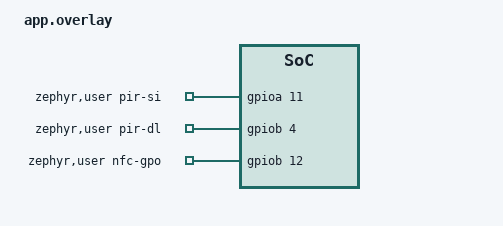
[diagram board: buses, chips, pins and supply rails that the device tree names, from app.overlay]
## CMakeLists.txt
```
#
# Copyright (c) 2025 HARDWARIO a.s.
#
# SPDX-License-Identifier: Apache-2.0
#

cmake_minimum_required(VERSION 3.20.0)

# Debug build (debug.conf in EXTRA_CONF_FILE): also apply debug.overlay, which
# locks the MSI to the LSE (msi-pll-mode). debug.conf sets CONFIG_PM=n, so the
# kernel tick is SysTick on the free-running MSI (~1.2 % off) instead of LPTIM
# on the LSE. Kconfig cannot add a devicetree overlay, and Kconfig is not
# parsed yet here, so key on the fragment name before find_package(Zephyr).
if(EXTRA_CONF_FILE MATCHES "(^|;|/)debug\\.conf(;|$)")
  list(APPEND EXTRA_DTC_OVERLAY_FILE ${CMAKE_CURRENT_SOURCE_DIR}/debug.overlay)
endif()

find_package(Zephyr REQUIRED HINTS $ENV{ZEPHYR_BASE})
project(sticker)

# Module patches (zephyr/patches.yml, applied by `west patch apply`). A LoRaWAN
# image built without them silently misses the fix, so refuse to build instead.
# Each patch leaves a "STICKER-<issue>" marker in the patched source. Checked at
# configure time and again on every build: `west update` resets the module and
# an incremental build (incl. the one `west flash` runs) does not reconfigure.
if(CONFIG_LORAWAN AND DEFINED ZEPHYR_LORAMAC_NODE_MODULE_DIR AND NOT STICKER_ALLOW_UNPATCHED_MODULES)
  set(FILE ${ZEPHYR_LORAMAC_NODE_MODULE_DIR}/src/mac/LoRaMac.c)
  set(MARKER STICKER-419)
  include(${CMAKE_CURRENT_SOURCE_DIR}/cmake/check_module_patch.cmake)
  add_custom_target(sticker_module_patch_check ALL
    COMMAND ${CMAKE_COMMAND} -DFILE=${FILE} -DMARKER=${MARKER}
            -P ${CMAKE_CURRENT_SOURCE_DIR}/cmake/check_module_patch.cmake
    COMMENT "Checking STICKER module patches")
  add_dependencies(app sticker_module_patch_check)
endif()

# Firmware version + source baked into the image (logged at boot, reported by
# the GetInfo command). CI passes the numeric version components and build type
# via -DAPP_VERSION_* / -DAPP_BUILD_TYPE (see .github/workflows/build.yml):
#   tag v1.3.4 -> 1/3/4, type 0 (MAIN)
#   branch/PR  -> the version below, type 1 (DEV)
# Local builds (no override) use the version below and are type 2 (CUSTOM).
# Keep it at the release this branch builds towards. The debug/release config
# is a separate axis (CONFIG_FW_DEBUG), not set here.
if(NOT DEFINED APP_VERSION_MAJOR)
  set(APP_VERSION_MAJOR 2)
  set(APP_VERSION_MINOR 0)
  set(APP_VERSION_PATCH 0)
endif()
if(NOT DEFINED APP_BUILD_TYPE)
  set(APP_BUILD_TYPE 2) # CUSTOM
endif()
add_compile_definitions(
  APP_VERSION_MAJOR=${APP_VERSION_MAJOR}
  APP_VERSION_MINOR=${APP_VERSION_MINOR}
  APP_VERSION_PATCH=${APP_VERSION_PATCH}
  APP_BUILD_TYPE=${APP_BUILD_TYPE})
message(STATUS "Firmware version: ${APP_VERSION_MAJOR}.${APP_VERSION_MINOR}.${APP_VERSION_PATCH} (build type ${APP_BUILD_TYPE})")

# Shared headers (sticker/drivers/...) live in the repo's top-level include/.
target_include_directories(app PRIVATE ${CMAKE_CURRENT_SOURCE_DIR}/../include)

list(APPEND CMAKE_MODULE_PATH ${ZEPHYR_BASE}/modules/nanopb)
include(nanopb)

# Note: nanopb generates src/app_config.pb.{c,h} here; west configen generates
# src/app_config.{c,h} (struct/Settings/shell) from app_config.yml. Different
# extensions, same stem — no clash.
zephyr_nanopb_sources(app src/app_config.proto)

target_sources_ifdef(CONFIG_ADC app PRIVATE src/app_analog.c)
target_sources_ifdef(CONFIG_ADC app PRIVATE src/app_battery.c)
target_sources_ifdef(CONFIG_RADIO_P2P app PRIVATE src/app_radio_p2p.c)
target_sources_ifdef(CONFIG_DS28E17 app PRIVATE src/app_machine_probe.c)
target_sources_ifdef(CONFIG_LIS2DH app PRIVATE src/app_accel.c)
target_sources_ifdef(CONFIG_LORAWAN app PRIVATE src/app_radio_lrw.c)
# app_report.c owns the periodic sample/history cadence via app_radio, not
# just the LoRaWAN uplink -- compiled unconditionally so sampling,
# history capture and store-and-forward keep working with no radio linked in
# at all. Two independent reasons converge here: #395's CONFIG_RADIO_LORAWAN=n
# debug variant, and #118's P2P bench overlay (CONFIG_RADIO_LORAWAN=n +
# CONFIG_RADIO_P2P=y). Its own app_radio_* calls route to whichever transport
# is compiled in, and app_radio.c handles "neither" itself.
target_sources(app PRIVATE src/app_report.c)
target_include_directories_ifdef(CONFIG_LORAWAN app PRIVATE
  ${ZEPHYR_LORAMAC_NODE_MODULE_DIR}/src/mac
  ${ZEPHYR_LORAMAC_NODE_MODULE_DIR}/src/mac/region
  ${ZEPHYR_LORAMAC_NODE_MODULE_DIR}/src/system
  ${ZEPHYR_LORAMAC_NODE_MODULE_DIR}/src/boards
)
target_sources_ifdef(CONFIG_OPT3001 app PRIVATE src/app_opt3001.c)
target_sources_ifdef(CONFIG_MPL3115A2 app PRIVATE src/app_mpl3115a2.c)
target_sources_ifdef(CONFIG_POWEROFF app PRIVATE src/app_power.c)
target_sources_ifdef(CONFIG_SHELL app PRIVATE src/app_ats.c)
target_sources_ifdef(CONFIG_SHT4X app PRIVATE src/app_sht4x.c)
target_sources_ifdef(CONFIG_W1 app PRIVATE src/app_ds18b20.c)
target_sources_ifdef(CONFIG_W1 app PRIVATE src/app_w1.c)
target_sources_ifdef(CONFIG_W1 app PRIVATE src/app_w1_slots.c)
target_sources_ifdef(CONFIG_WATCHDOG app PRIVATE src/app_wdog.c)
target_sources_ifdef(CONFIG_APP_BUZZER app PRIVATE src/app_buzzer.c)
target_sources_ifdef(CONFIG_APP_CALIBRATION app PRIVATE src/app_calibration.c)
target_sources(app PRIVATE src/app_alarm.c)
target_sources(app PRIVATE src/app_alarm_rules.c)
target_sources(app PRIVATE src/app_clock.c)
target_sources(app PRIVATE src/app_cmd.c)
target_sources(app PRIVATE src/app_compose.c)
target_sources(app PRIVATE src/app_config.c)
target_sources(app PRIVATE src/app_counters.c)
target_sources(app PRIVATE src/app_eventlog.c)
target_sources(app PRIVATE src/app_hall.c)
target_sources(app PRIVATE src/app_history.c)
target_sources(app PRIVATE src/app_input.c)
target_sources(app PRIVATE src/app_led.c)
target_sources(app PRIVATE src/app_config_ingest.c)
target_sources(app PRIVATE src/app_nfc.c)
target_sources(app PRIVATE src/app_ccm.c)

# app_ccm's block cipher: the STM32WL HW AES peripheral by default. When it is
# disabled (CONFIG_APP_CCM_HW_AES=n, e.g. the variant-A soft fallback) the CCM
# layer uses the LoRaMac soft-SE AES instead — pull that source + its prekeyed
# API in (the HW build needs neither).
# With LoRaWAN on, the loramac-node library already links that aes.c.
if(NOT CONFIG_APP_CCM_HW_AES)
  set(SOFT_SE_DIR ${ZEPHYR_LORAMAC_NODE_MODULE_DIR}/src/peripherals/soft-se)
  if(NOT CONFIG_HAS_SEMTECH_SOFT_SE)
    target_sources(app PRIVATE ${SOFT_SE_DIR}/aes.c)
  endif()
  target_include_directories(app PRIVATE ${SOFT_SE_DIR})
  set_source_files_properties(src/app_ccm.c ${SOFT_SE_DIR}/aes.c
    PROPERTIES COMPILE_DEFINITIONS "AES_ENC_PREKEYED")
endif()
target_sources_ifdef(CONFIG_APP_PYQ1648 app PRIVATE src/app_pyq1648.c)
target_sources(app PRIVATE src/app_sensor.c)
# Generated by `west sensorgen` from src/app_sensor_types.yaml (#430).
target_sources(app PRIVATE src/app_sensor_types.c)
target_sources(app PRIVATE src/app_settings.c)
target_sources(app PRIVATE src/app_radio.c)
target_sources(app PRIVATE src/app_slot.c)
target_sources(app PRIVATE src/main.c)
```

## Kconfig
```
#
# Copyright (c) 2025 HARDWARIO a.s.
#
# SPDX-License-Identifier: Apache-2.0
#

menu "Application"

config RADIO_LORAWAN
	bool "LoRaWAN radio transport"
	default y
	select LORAWAN if LORA
	help
	  App-level name for the LoRaWAN transport (issue #395) — pairs with
	  RADIO_P2P below as the two selectable radio transports. `select
	  LORAWAN if LORA` only forces the underlying Zephyr subsystem ON
	  when this is y AND the LORA radio driver is present (native_sim
	  test builds have neither — `select` on a symbol whose own
	  dependencies aren't met is a hard Kconfig error, not a silent
	  no-op, hence the `if LORA` guard); turning this off on real HW
	  (nothing else in this tree selects LORAWAN) leaves it at its own
	  default (off), disabling all radio transmission. Telemetry/alarm
	  sampling and history capture keep working with no radio
	  (app_report.c owns that cadence, not the uplink) — only the actual
	  send is skipped.

	  ~41 KB flash / ~15 KB RAM when off (issue #395) — the single
	  biggest lever of any toggle in this tree, but also the biggest
	  behavioral change (no radio at all), which is why it stays on by
	  default rather than joining debug.conf's OFF-by-default set.

config RADIO_P2P
	bool "Raw-LoRa P2P radio transport (#118)"
	depends on LORA
	default y
	# TOWER's ACK window: TX-done straight into RX (doc/plan/470 §13.1).
	# Without it (native_sim, a driver lacking it) app_radio_p2p.c falls
	# back to lora_send() + lora_recv_async().
	imply LORA_SEND_RECV_ASYNC
	# Boosted LNA gain on every lora_* reception, ~+2 dB for ~+0.1 uA at a
	# 900 s report (doc/plan/470 §3.3, Hynek 2026-10-08).
	imply LORA_RX_BOOSTED_GAIN
	# The fsk PHY profile, TOWER-native GFSK (#490); without it
	# p2p-modulation fsk refuses to start.
	imply LORA_FSK
	# The fsk packet's CRC16 is computed in software (p2p_fsk_wrap()).
	select CRC
	help
	  App-level name for the raw-LoRa point-to-point transport
	  (app_radio_p2p.c, issue #118) — pairs with RADIO_LORAWAN above as the two
	  selectable radio transports. Reserved as an inert placeholder by
	  #395 and wired up here when the P2P work merged; it was briefly
	  named APP_LORA_P2P on the feat-p2p branch, so out-of-tree overlays
	  carrying that name need updating.

	  Unlike RADIO_LORAWAN, which `select`s an underlying Zephyr
	  subsystem, this compiles app-owned code that talks to drivers/lora
	  directly — hence `depends on LORA` rather than a `select` (and it
	  therefore drops out on native_sim test builds, which have no radio,
	  without needing RADIO_LORAWAN's `if LORA` guard).

	  Which transport actually brings up the shared SX126x radio is a
	  runtime choice (`radio-mode`, #271), not a build-time one: both
	  stacks link into the same image when both are y. Turning this off
	  reclaims flash on builds that never need P2P — the flash-tight
	  debug overlay does exactly that (doc/p2p.md §11).

config APP_VERBOSE_LOGGING
	bool "Enable verbose parameter logging"
	default y
	help
	  Enable verbose logging of all configuration parameters.
	  This adds detailed logging for NFC parameters and other
	  configuration changes. Disable to save flash space.

config FW_DEBUG
	bool "Debug firmware indication"
	default n
	help
	  Enable debug firmware LED indication.
	  When enabled, the periodic LED blink shows green + yellow
	  instead of just green to indicate debug build.

config APP_DEBUG_AUTOSUSPEND_S
	int "Debug auto-suspend idle timeout (seconds, 0 = disabled)"
	depends on FW_DEBUG && POWEROFF && SHELL_BACKEND_RTT
	default 7200
	help
	  On the Debug build, after this many seconds with no RTT/shell
	  activity the device enters deep-sleep (STM32 Shutdown via
	  sys_poweroff) so a forgotten bench unit stops draining its
	  battery — Debug FW runs with CONFIG_PM=n, so the CPU never sleeps
	  and the quiescent draw is high. Default 7200 s (2 h). 0 disables
	  the auto-suspend.
	  Wake is by NRST / power-cycle (clean boot; NVS identity and
	  LoRaWAN keys survive in flash).

config APP_BATTERY_BOOT_GATE
	bool "Stay off when the battery is too low at boot"
	default y
	depends on HAS_POWEROFF && ADC
	select POWEROFF
	help
	  #496: measure the battery first thing at boot, before the IWDG,
	  the radio, NVS writes and the sensors. Below
	  APP_BATTERY_BOOT_MIN_MV the STICKER does not start: it powers
	  down to STM32WL Shutdown and stays off until NRST / a
	  power-cycle (battery replacement) runs the check again. A
	  depleted cell otherwise boot-loops on brownout, writing the P2P
	  FCnt base to flash and sending a Hello on every boot. A failed
	  ADC read boots normally.

config APP_BATTERY_BOOT_MIN_MV
	int "Minimum battery voltage to start (mV)"
	depends on APP_BATTERY_BOOT_GATE
	default 1800
	range 1000 3600
	help
	  Battery voltage below which the STICKER stays off at boot
	  (APP_BATTERY_BOOT_GATE). 1.8 V is the STM32WLE5 / flash minimum
	  (1.71 V) plus margin. Independent of the low-battery alarm
	  threshold (`battery_level`).

config APP_LORAWAN_1_1
	bool "Use LoRaWAN 1.1.x crypto for OTAA"
	default n
	help
	  Enable LoRaWAN 1.1.x crypto for OTAA join: feed `lrw_nwkkey` into
	  the NwkKey slot (distinct from AppKey). When disabled (default,
	  LoRaWAN 1.0.x), the firmware copies `radio_appkey` into both the
	  NwkKey and AppKey slots so the JoinRequest MIC is computed from
	  AppKey — required for 1.0.x network servers (TTN, ChirpStack,
	  Helium).

	  Enabling this also requires the LoRaMac library to be built with
	  USE_LRWAN_1_1_X_CRYPTO=1; the Kconfig only flips the app-level
	  key wiring.

config APP_NFC_ENCRYPTION
	bool "Encrypt the NFC command/config channel (AES-CCM)"
	default y
	help
	  Production default (y): NFC command records (hio.stck:cmd) and config
	  records (hio.stck:cfg) must be AES-CCM encrypted with the device
	  secret_key and a strictly increasing nonce, and the response written
	  back (hio.stck:rsp) is encrypted the same way. Without the key, the
	  only thing a phone can read is the plaintext info record (hio.stck:inf).

	  Disable (n) ONLY for a bench validation build, to drive the NFC command
	  and config channel in plaintext without provisioning a secret key or
	  managing nonces. Such a build logs a loud boot warning. NEVER ship a
	  build with this turned off.

config APP_CCM_HW_AES
	bool "Use the STM32WL hardware AES peripheral for NFC AES-CCM"
	depends on APP_NFC_ENCRYPTION && SOC_SERIES_STM32WLX
	default y
	help
	  Back the app_ccm (RFC 3610 AES-CCM) block cipher with the STM32WL on-die
	  AES peripheral (register-level, no HAL/Zephyr-crypto dependency). This is
	  what lets the build drop mbedTLS entirely (~6.5 KB flash, #261).

	  Disable (n) to fall back to the LoRaMac soft-SE AES (peripherals/soft-se,
	  already in flash) as the block cipher instead — the CCM layer is identical,
	  only the primitive differs. The host unit tests use this software path.

config APP_CMD_DEBUG_SHELL
	bool "Shell injector for downlink command dispatcher"
	depends on SHELL
	default n
	help
	  Enable `tester cmd <transport> <hex>` for end-to-end testing
	  of the downlink command dispatcher without a LoRaWAN gateway.
	  The hex payload is fed to app_cmd_handle as if it had arrived
	  from the given transport (lrw or nfc) and the encoded response
	  is logged and (for lrw) queued on port 85.

config APP_HISTORY
	bool "Sensor history store-and-forward"
	default y
	help
	  Disable to drop the history (and the event log) entirely, e.g. in the
	  provisioning image. History commands then report no data.

config APP_HISTORY_FLASH
	bool "Persist sensor history in the history_partition flash"
	depends on APP_HISTORY
	default y
	help
	  Store the sensor history store-and-forward buffer in the dedicated
	  history_partition flash (NVS), surviving reboot and power loss.
	  Disable to use a __noinit RAM ring of CONFIG_APP_HISTORY_BYTES
	  instead; data is then lost on power loss.

	  Builds with this enabled must keep CONFIG_FLASH_LOAD_SIZE at the
	  history_partition offset so the linker stops the image from growing
	  into the runtime-written flash (see prj.conf); builds with it
	  disabled (debug.conf) may relax the budget up to the
	  storage_partition offset.

config APP_HISTORY_BYTES
	int "History RAM fallback ring size (bytes)"
	default 1024
	help
	  Size of the in-RAM history ring used when CONFIG_APP_HISTORY_FLASH=n.
	  Record size is variable (5-33 B) depending on the enabled sensor set.

config APP_CALIBRATION
	bool "Factory calibration mode (magnet-triggered)"
	default y
	help
	  Compile in the magnet-triggered factory calibration mode
	  (app_calibration.c): boots into a dedicated LED/LoRaWAN test loop
	  that reads every enabled sensor and reports over a fixed uplink,
	  instead of normal application behavior.

	  Disable for bench sessions that don't need to calibrate hardware
	  (e.g. a pure radio/transport test) to free flash/RAM for what IS
	  under test — see app/debug.conf's variant table.

config APP_PYQ1648
	bool "PIR motion sensor (PYQ1648)"
	default y
	help
	  Compile in the PIR motion-detector driver wrapper (app_pyq1648.c).
	  Default y to match shipped behavior — both this and
	  CONFIG_APP_BUZZER stay compiled in on a normal build, since which
	  one is actually active is a runtime, per-unit choice
	  (cap-gpio-mode pir / buzzer, they share pins, #90/#338/#498).
	  Disable only for a bench session that knows it needs neither.

config APP_BUZZER
	bool "Buzzer / melody output (#338)"
	default y
	help
	  Compile in the buzzer/melody driver wrapper (app_buzzer.c) and its
	  shell (`ats buzz ...`) and remote-command (NFC/LoRaWAN play-melody)
	  surfaces. Default y to match shipped behavior (see
	  CONFIG_APP_PYQ1648 above) — disable only for a bench session that
	  knows it needs neither PIR nor buzzer.

endmenu

menu "Zephyr Kernel"
source "Kconfig.zephyr"
endmenu
```

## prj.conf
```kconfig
# System heap backs only the 1-Wire bus scan (app_w1.c), which k_mallocs one
# ~16 B scan_item per ROM up to APP_W1_SCAN_MAX=32 (≈768 B incl. sys_heap block
# overhead). 1024 B holds the full 32-device cap with margin; the old 2048 was
# ~2x oversized (#221.2).
CONFIG_HEAP_MEM_POOL_SIZE=1024
CONFIG_IDLE_STACK_SIZE=512
# ISR/main sized from HW high-water marks (CONFIG_INIT_STACKS, 2026-10-09,
# release + debug, join/report/downlink/SetParam/GetConfig): ISR 192 B, main
# 992 B (boot incl. settings load and the boot ConfigDump). >= 2x margin.
CONFIG_ISR_STACK_SIZE=1024
CONFIG_MAIN_STACK_SIZE=2048
CONFIG_SYSTEM_WORKQUEUE_STACK_SIZE=2048

CONFIG_REBOOT=y
# Drop the "*** Booting Zephyr ***" banner (~0.3 KB flash, #220); the boot log
# line "Firmware version: ..." is our own LOG_INF and is unaffected.
CONFIG_BOOT_BANNER=n
# Release has no console backend, so printk() output and the fault-dump text go
# nowhere — yet printk, the libc vfprintf behind it and the fault-dump strings
# cost ~3 KB flash. Faults still reset the device and the reset cause stays
# visible in GetInfo (HWINFO, #88). debug.conf turns both back on.
CONFIG_PRINTK=n
CONFIG_FAULT_DUMP=0
CONFIG_I2C=y
# Bus recovery (H-6): app_sensor calls i2c_recover_bus() after a run of failed
# reads to bit-bang 9 clocks and free a wedged bus; without this it returns
# -ENOSYS and a stuck bus leaves every onboard sensor permanently dead. Needs
# scl-gpios/sda-gpios on the &i2c1 node (board DTS).
CONFIG_I2C_STM32_BUS_RECOVERY=y
CONFIG_SENSOR=y
CONFIG_PM=y
CONFIG_PM_DEVICE=y
# Device runtime PM stays ON (low idle current: it on-demand-suspends idle
# peripherals — worth ~200 µA vs disabling it globally, measured on HW). The
# NFC-on-release failure it caused is handled in the NFC layer, not by turning PM
# off: servicing one encrypted tag command is many back-to-back i2c1 transfers
# and, on release, the CPU dropped into Stop2 in the field-off gaps between them,
# which corrupts the i2c1 (ST25DV) tag I/O (release-only; debug runs PM=n and
# never sleeps). app_nfc.c now holds a SUSPEND_TO_IDLE policy lock for the whole
# RF session (nfc_keep_awake, armed from the GPO ISR on RF field-on/write), so no
# Stop2 lands mid-operation; the lock is released after a short RF-quiet window so
# deep sleep resumes. The NFC poll is also event-driven (waits forever on the GPO
# when idle, no periodic Stop2 wake). Validated on hardware.
CONFIG_PM_DEVICE_RUNTIME=y

CONFIG_SPI=y

CONFIG_NVS=y
CONFIG_FLASH=y
CONFIG_FLASH_MAP=y
CONFIG_SETTINGS=y
# Without these a full settings_save() walks every NVS name record for every
# key: 3-4 s of CPU, longer than a radio exchange may wait for it (app_radio.c).
CONFIG_NVS_LOOKUP_CACHE=y
CONFIG_SETTINGS_NVS_NAME_CACHE=y
CONFIG_CRC=y # history ring page-header integrity (app_history.c, #265)

# Link-Time Optimization: defer final codegen to link time so the compiler sees
# the whole program and eliminates dead code across translation-unit boundaries
# (LoRaMac Class B/C + FUOTA variants STICKER never calls).
# Reclaims ~19 KB flash (release ~99.9% → ~88.5%), restoring headroom for bug
# fixes that otherwise fail to link (#263). ISR_TABLES_LOCAL_DECLARATION is
# required for the vector table to build correctly under LTO. Note: setting
# CONFIG_LTO=y on the west command line silently does not apply — keep it here.
CONFIG_LTO=y
CONFIG_ISR_TABLES_LOCAL_DECLARATION=y

# Image size budget — must equal the history_partition offset (sticker.dts):
# with CONFIG_APP_HISTORY_FLASH=y (release default) the history ring rewrites
# that area at runtime, and NVS settings + LoRaWAN NVM always rewrite the
# storage_partition. An image leaking into either region gets corrupted in
# flash → hard fault on next boot, recoverable only by mass erase. With this
# set, the linker fails the build instead ("region ROM overflowed").
# #265 grew this 0x28000 → 0x2C000 (code 160 KB → 176 KB) after the history
# partition shrank to 64 KB @ 0x2C000; #302 grew it again 0x2C000 → 0x34000
# (code 176 KB → 208 KB) after history shrank further to 32 KB @ 0x34000.
# debug.conf (history in RAM) relaxes this to the storage offset 0x3C000.
CONFIG_FLASH_LOAD_SIZE=0x34000

CONFIG_LORA=y
CONFIG_LORAMAC_REGION_AS923=y
CONFIG_LORAMAC_REGION_AU915=y
CONFIG_LORAMAC_REGION_EU868=y
CONFIG_LORAMAC_REGION_US915=y
CONFIG_LORAWAN_NVM_SETTINGS=y
# CONFIG_LORAWAN itself now comes from CONFIG_RADIO_LORAWAN's `select`
# (app/Kconfig, default y, issue #395) instead of a flat assignment here —
# turning CONFIG_RADIO_LORAWAN off (e.g. debug.conf's radio-free bench
# profile) is the one place that needs to change.
# CONFIG_LORAWAN_SYSTEM_MAX_RX_ERROR stays at the Zephyr default (20). Larger
# values overflow the uint8 RX symbol timeout in the SX126x driver on fast RX1
# data rates (US915 DR>=2, EU868 DR6) and every downlink is lost.
# Bounded MAC-confirm wait in lorawan_join()/lorawan_send() (sticker-zephyr,
# #181): a lost confirm returns -ETIMEDOUT instead of wedging m_work_q. Must stay
# below LRW_HEARTBEAT_TIMEOUT_MS (30 s, app_radio_lrw.c, BUILD_ASSERT) so the graceful
# path wins over the #182 watchdog-liveness reset; legitimate waits are ~7-10 s.
CONFIG_LORAWAN_CONFIRM_TIMEOUT_MS=20000

# Wall-clock: STM32 RTC (LSE-backed) set from LoRaWAN DeviceTimeReq. See app_clock.c.
CONFIG_RTC=y
CONFIG_RTC_STM32=y

CONFIG_LIS2DH_ACCEL_RANGE_4G=y
CONFIG_LIS2DH_BLOCK_DATA_UPDATE=y
CONFIG_LIS2DH_ODR_5=y
CONFIG_LIS2DH_OPER_MODE_LOW_POWER=y
CONFIG_LIS2DH_TRIGGER_GLOBAL_THREAD=y

CONFIG_ENTROPY_GENERATOR=y

CONFIG_WATCHDOG=y
CONFIG_WDT_DISABLE_AT_BOOT=y

# Reset-cause readback reported in GetInfo so watchdog/brownout resets are
# visible in the field (#88).
CONFIG_HWINFO=y

CONFIG_ADC=y

CONFIG_LIS2DH=y
CONFIG_MPL3115A2=y
CONFIG_OPT3001=y
CONFIG_SHT4X=y
CONFIG_W1=y

CONFIG_NET_BUF=y
CONFIG_NANOPB=y

# mbedTLS is gone (#261): the NFC AES-CCM channel is now served by app_ccm (RFC
# 3610) over the STM32WL on-die AES peripheral, saving ~6.5 KB flash. LoRaMac uses
# its own soft-SE AES, independent of this.
```

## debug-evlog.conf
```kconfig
# Event log bench image: layer on debug.conf + debug-history-flash.conf
# (with debug-history-flash.overlay). Real flash ring for history + event log,
# RTT shell + logs, accelerometer on; drops what the motion test does not need
# to fit the 224 KB code partition. EU868 only (debug.conf), no 1-Wire.
CONFIG_LIS2DH=y
CONFIG_SHT4X=n
CONFIG_OPT3001=n
CONFIG_APP_CALIBRATION=n
CONFIG_APP_BUZZER=n
CONFIG_APP_PYQ1648=n
CONFIG_W1=n
CONFIG_LOG=n
CONFIG_SHELL_HELP=n
CONFIG_SHELL_HELP_ON_WRONG_ARGUMENT_COUNT=n
```

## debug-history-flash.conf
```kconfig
# Copyright (c) 2026 HARDWARIO a.s.
# SPDX-License-Identifier: Apache-2.0
#
# Pair with debug-history-flash.overlay (16 KB history_partition @ 0x38000,
# code_partition grown to 224 KB). Overrides debug.conf's history-in-RAM
# fallback so a debug build (full RTT shell) can exercise the real flash-ring
# backend: persistence across reboot, page wrap/eviction (8 x 2 KB pages wrap
# in minutes, not hours), torn-tail recovery, and the clock-sync base-time
# backfill (app_history_on_clock_sync) — none of which are testable on a
# stock debug build (CONFIG_APP_HISTORY_FLASH=n) or a stock release build (no
# shell to drive `history *` / `w1` / `alarm` interactively).
#
# Usage: west build -b sticker . -p always -- \
#   -DEXTRA_CONF_FILE="debug.conf;debug-history-flash.conf" \
#   -DEXTRA_DTC_OVERLAY_FILE=debug-history-flash.overlay

CONFIG_APP_HISTORY_FLASH=y

# Must match debug-history-flash.overlay's code_partition size (224 KB) — the
# linker fails the build ("region ROM overflowed") instead of letting the
# image grow into the runtime-written history_partition (see prj.conf).
CONFIG_FLASH_LOAD_SIZE=0x38000
```

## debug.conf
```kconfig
# Float printf support is not needed: all %f log/shell output was converted to
# integer formatting (APP_FP* in app_log.h), freeing debug flash.
CONFIG_CBPRINTF_FP_SUPPORT=n
# prj.conf turns printk and the fault dump off for release (no console there);
# debug keeps both — RTT console output and readable fault reports.
CONFIG_PRINTK=y
CONFIG_FAULT_DUMP=2

CONFIG_FW_DEBUG=y

CONFIG_CONSOLE=y
CONFIG_RTT_CONSOLE=y

CONFIG_THREAD_NAME=y

CONFIG_USE_SEGGER_RTT=y

CONFIG_LOG=n

# Logging mode: MINIMAL routes LOG_* straight to printk (-> RTT console via
# CONFIG_RTT_CONSOLE), with no deferred log thread, no internal buffer and no
# backend layer. Saves ~14 KB flash + ~11 KB RAM vs deferred mode. Trade-off:
# no timestamps/prefixes in the log line, and build-time level filtering only
# (CONFIG_LOG_MAX_LEVEL still applies, but the `log` shell cmd can't change
# levels at runtime).
# CONFIG_LOG_MODE_MINIMAL=y

# --- Deferred-logging config (full RTT backend, timestamps, runtime levels) ---
# ENABLED (was MINIMAL): MINIMAL routes LOG_* synchronously via printk, which
# blocks the calling context long enough to make the STICKER miss the tight
# high-DR (SF7) Class-A RX1 window -> downlinks (e.g. fPort 85 req_history) are
# not received. Deferred mode drains logs on a separate thread with a DROP-mode
# backend, so logging never stalls the RX timing. (~14 KB flash / ~11 KB RAM.)
# Buffers trimmed vs the reference block to fit the near-full debug RAM budget
# (deferred adds ~11 KB; default 2048 sizes overflowed RAM by ~1.7 KB).

CONFIG_SHELL=y
CONFIG_SHELL_BACKEND_RTT_BUFFER=0
CONFIG_SHELL_BACKEND_RTT=y
CONFIG_SHELL_ECHO_STATUS=n
CONFIG_SHELL_HELP_ON_WRONG_ARGUMENT_COUNT=y
CONFIG_SHELL_HELP=y
CONFIG_SHELL_LOG_BACKEND=n
CONFIG_SHELL_MINIMAL=y
CONFIG_SHELL_PROMPT_RTT=""
CONFIG_SHELL_RTT_RX_POLL_PERIOD=200
CONFIG_SHELL_STACK_SIZE=4096
CONFIG_SHELL_VT100_COMMANDS=n

# I2C/LoRa-PHY shells dropped to keep the debug image inside the
# CONFIG_FLASH_LOAD_SIZE budget (see prj.conf); re-enable locally if needed.
CONFIG_I2C_SHELL=n

# Down (host->target, shell RX) doesn't need to match the up/log buffer: the
# Zephyr default is 16 B, but the shell needs enough for a full command line
# (e.g. `ats cmd <hex>` payloads) — 256 B is a comfortable compromise, freeing
# ~768 B of RAM that was otherwise just mirroring the up-buffer size for no
# documented reason.
CONFIG_SEGGER_RTT_BUFFER_SIZE_DOWN=256
CONFIG_SEGGER_RTT_BUFFER_SIZE_UP=1024

CONFIG_SEGGER_RTT_SECTION_CUSTOM=y

CONFIG_PM=n

# Deep-sleep / auto-suspend (#113): sys_poweroff() puts the STM32WL into Shutdown
# after CONFIG_APP_DEBUG_AUTOSUSPEND_S of RTT/shell inactivity, so a forgotten
# debug unit (PM=n, CPU never sleeps) stops draining its battery. Wake = NRST.
CONFIG_POWEROFF=y

CONFIG_LORA_LOG_LEVEL_DBG=n
CONFIG_SENSOR_LOG_LEVEL_DBG=n
CONFIG_W1_LOG_LEVEL_DBG=n

# Debug-only region trim (release keeps AS923/AU915/US915): the bench only ever
# exercises EU868 (TTN + ChirpStack), and the near-full debug image needs the
# flash/RAM headroom. Measured ~5.9 KB flash / ~0.7 KB RAM for AU915+US915
# (2026-06-17 analysis); AS923 adds ~2.6 KB flash (#409 A6). A trimmed region
# stored in NVM leaves the radio silent (#409 A1), never on the wrong band.
CONFIG_LORAMAC_REGION_AS923=n
CONFIG_LORAMAC_REGION_AU915=n
CONFIG_LORAMAC_REGION_US915=n

CONFIG_LORA_SHELL=n

# Debug drops the P2P transport (release keeps it, default y): the near-full
# debug image only has ~4.75 KB headroom vs release's ~58.5 KB (doc/p2p.md
# §11, measured 2026-08-17) — not enough for the dual-stack addition.
CONFIG_RADIO_P2P=n

# The 3 new p2p_* config fields (#118) grow g_app_config (BSS) by 12 B even
# with CONFIG_RADIO_P2P=n above -- config schema size is independent of
# whether the transport code itself is compiled in. The already-99.92%-full
# debug image (0 B free before this) squeezes that straight out of the
# __noinit history RAM ring (CONFIG_APP_HISTORY_FLASH=n below); trimming by
# just the 12 B needed leaves ~0 B free again, so shave 32 B (1024 -> 992) for
# a small working margin instead.
CONFIG_APP_HISTORY_BYTES=992

# Enable stack usage diagnostics for the m_work_q probe in app_radio_lrw.c
CONFIG_INIT_STACKS=y
CONFIG_THREAD_STACK_INFO=y

CONFIG_APP_CMD_DEBUG_SHELL=y

# The debug image does not fit under the history_partition offset, so keep
# history in RAM and relax the image budget up to the storage_partition offset
# (sticker.dts) — NVS settings + LoRaWAN NVM still rewrite storage at runtime,
# so the linker must keep the image out of it (see prj.conf for the rationale).
CONFIG_APP_HISTORY_FLASH=n
CONFIG_FLASH_LOAD_SIZE=0x3C000


# The v1.4.0 debug image is near-full; the 1-Wire slot/teach feature does
# not fit at INF. Cap RTT logging to WRN to make room (shell + LED still
# work for testing; raise to 4 locally for full INF/DBG diagnostics).
# Compile-time level filtering only. Runtime filtering makes every LOG_* call
# site test a per-source dynamic level, but nothing here can change those levels
# at runtime (CONFIG_LOG_CMDS is off, no log_filter_set() caller), so it only
# cost ~6.2 KB flash + 256 B RAM. Raising CONFIG_LOG_MAX_LEVEL to 3 (INF) fits
# in roughly the space this frees.

# =============================================================================
# Optional subsystems — the highest-value ones OFF by default here to give
# debug.conf real headroom (issue #394: this build used to sit at 98.48%
# flash / 99.92% RAM with everything on — only ~20-170 B "free" per the
# linker's own report, and that margin turned out to be unsafe in practice,
# not just tight: a system-heap write past the end of RAM crashed real HW at
# exactly that margin). Every line below (on or off) is a real, measured,
# independently-working Kconfig toggle — verified to build and link cleanly
# alone and in every combination tried.
#
# To re-enable one of the OFF-by-default toggles for a session: delete/
# comment its `=n` line below, or override on the command line without
# editing this file, e.g.:
#   west build -b sticker app -- -DEXTRA_CONF_FILE=debug.conf -DCONFIG_W1=y
#
# Measured savings (this build, 2026-08-19; baseline = mainline debug.conf
# with every toggle below at its Kconfig default, i.e. all ON: FLASH 242028 B
# / 98.48%, RAM 65484 B / 99.92%). Ranked by flash impact:
#
# | Toggle                              | Flash saved |    RAM saved | What it drops | Default here |
# |-------------------------------------|------------:|-------------:|---------------|:------------:|
# | CONFIG_RADIO_LORAWAN=n              |    ~41.0 KB |     ~15.1 KB | LoRaMac stack + radio HAL + app_radio_lrw.c — **disables ALL radio transmission** (telemetry/alarm still sampled + history-captured locally, just never sent). Biggest lever by far, but a much bigger behavioral change than the others below — opt in explicitly, not part of the default set. App-level name wrapping the underlying CONFIG_LORAWAN (`select`), pairs with CONFIG_RADIO_P2P below. | **ON** (opt out with `-DCONFIG_RADIO_LORAWAN=n`) |
# | CONFIG_W1=n                         |    ~20.3 KB |      ~0.5 KB | 1-Wire bus: DS18B20, DS28E17 machine-probe bridge, ROM-bound slot registry (app_w1*.c, app_ds18b20.c, app_machine_probe.c) | OFF |
# | CONFIG_LIS2DH=n                     |     ~7.6 KB |      ~0.3 KB | Accelerometer (orientation, motion, free-fall) | OFF |
# | CONFIG_APP_BUZZER=n                 |     ~2.3 KB |      ~0.8 KB | Buzzer/melody HW variant (#338) + its shell/remote-command surface | OFF |
# | CONFIG_APP_PYQ1648=n                |     ~1.0 KB |      ~2.3 KB | PIR motion sensor (biggest single RAM win among the sensor toggles) | OFF |
# | CONFIG_SHT4X=n                      |     ~2.1 KB |      ~0.1 KB | Onboard temperature/humidity sensor | on (small win, not worth remembering to re-enable) |
# | CONFIG_APP_CALIBRATION=n            |     ~2.0 KB |      ~0.3 KB | Magnet-triggered factory calibration mode | on (ditto) |
# | CONFIG_OPT3001=n                    |    ~0.75 KB |         ~0 B | Ambient light sensor | on (negligible) |
# |-------------------------------------|------------:|-------------:|---------------|:------------:|
# | **4 OFF-by-default together**       |  **~31 KB** |  **~3.9 KB** | New default baseline: FLASH 85.46%, RAM 93.74% |
# | **+ CONFIG_RADIO_LORAWAN=n on top** |  **~72 KB** | **~19.0 KB** | Radio-free bench baseline: FLASH 68.36%, RAM 70.15% |
#
# CONFIG_RADIO_P2P (app/Kconfig) pairs with CONFIG_RADIO_LORAWAN above and
# is now wired to the real raw-LoRa P2P transport (#118) — it was an inert
# placeholder when this table was written. It is OFF in this file (see the
# headroom note further up); the two-STICKER bench overlay
# debug_p2p_bench.conf turns it back on and turns CONFIG_RADIO_LORAWAN off,
# which is the only build where P2P is exercised on a debug image.
#
# Not included above (known limitations / deliberately out of scope, see
# issue #395 for the full writeup):
# - CONFIG_DS28E17=n *alone* (keep plain W1/DS18B20, drop only the
#   machine-probe bridge) does NOT currently link — app_w1_slots.c's own
#   sensor-type registry references app_machine_probe_* unconditionally.
#   Use CONFIG_W1=n (drops both together) instead.
# - CONFIG_W1=y on top of this file with LoRaWAN on no longer fits the flash
#   budget (v1.5.0 #494 HIL, 2026-10-13: 316 B over even with
#   LOG_MAX_LEVEL=1, APP_CALIBRATION=n, OPT3001=n). Add
#   -DCONFIG_SHELL_HELP=n (fits at 99.79 %) or drop the radio
#   (-DCONFIG_RADIO_LORAWAN=n).
# - NFC, the alarm engine, hall/input counters, and history are NOT
#   independently toggleable today — each referenced from many more files
#   (app_compose.c, app_alarm.c, app_cmd.c, app_settings.c, ...) than a
#   single Kconfig flag away. Making any of them optional needs a dedicated
#   pass through those cross-references (see issue #395).
# - CONFIG_ADC=n (battery voltage) was not attempted — referenced from 6
#   files (calibration/alarm/sensor/cmd/lrw/main), and the voltage itself is
#   near-universally wanted in every telemetry frame, so unlikely to be worth
#   the effort for the (probably small) ADC driver footprint it would save.
CONFIG_W1=n
CONFIG_LIS2DH=n
CONFIG_APP_BUZZER=n
CONFIG_APP_PYQ1648=n
```

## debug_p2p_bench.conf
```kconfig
# P2P two-STICKER bench overlay for the DUT (#118, doc/p2p.md §14) -- layer
# this ON TOP of debug.conf:
#
#   west build -b sticker sticker/app -- \
#     -DEXTRA_CONF_FILE="debug.conf;debug_p2p_bench.conf"
#
# debug.conf alone drops CONFIG_RADIO_P2P (doc/p2p.md §11: the near-full
# debug image has no headroom for the dual-stack addition). This overlay flips
# it back on for bench testing and trims enough elsewhere to fit -- shell/RTT
# stay fully enabled (that IS the test's UI), history/watchdog/log depth are
# what give up the room, since none of them are under test here.
#
# Bench-only: do not use for anything other than the two-STICKER P2P rig.
#
# PRE-FLASH THE RADIO MODE (F-36). This overlay sets CONFIG_RADIO_LORAWAN=n, so
# an image built from it can only serve `radio-mode p2p`. A node whose NVS still
# says `lorawan` -- or `off`, which is the factory default (#350) -- has no
# transport here. app_radio_init() now logs "no transport for radio-mode N in
# this image; radio idle" and leaves the radio idle instead of returning -ENODEV
# into main.c's die(), so the node boots, keeps its shell and can be fixed in
# place:
#
#   ats config radio-mode p2p
#   ats config save
#   (reboot)
#
# Before that degrade landed, the same situation was a 60 s fatal reboot loop
# with roughly a nine-second shell window per cycle to type the fix into.
#
# 2026-08-18 HIL finding: the previous ~170 B "free" margin (per the linker's
# own static RAM report) was NOT a safe margin in practice -- a two-STICKER
# bench session hit reproducible BusFault/UsageFault crashes on real HW with
# the fault address landing exactly at/past the top of RAM (0x20010000 on
# this 64 KB part), both with and without CONFIG_RADIO_P2P=y (i.e. this is
# a general debug.conf RAM-exhaustion issue, not a P2P-specific bug -- tracked
# separately). Whatever lands last during static linking only had ~20-170 B
# to work with, which some runtime-computed structure (heap init, chunk
# bookkeeping, etc.) doesn't fit into. Trimmed further below for a real
# multi-hundred-byte margin instead of a barely-positive one.
CONFIG_RADIO_P2P=y

# History isn't under test; shrink the RAM ring (debug.conf already keeps
# history in RAM, CONFIG_APP_HISTORY_FLASH=n) to the smallest practical size.
CONFIG_APP_HISTORY_BYTES=32

# Watchdog isn't needed for an interactive bench session (no unattended
# operation to protect) and its callers are already CONFIG_WATCHDOG-guarded
# throughout (app_radio_lrw.c, app_radio_p2p.c, main.c), so disabling it is safe.
CONFIG_WATCHDOG=n

# Deferred-logging buffers: still enough for the P2P module's own LOG_INF
# lines (frame hex dumps top out around ~500 B, larger than any single log
# buffer here, but the ring drains continuously so this is about steady-state
# capacity, not one message's worst case) at roughly a third of debug.conf's
# sizing (cut further than the original half after the crash above).
CONFIG_LOG_BUFFER_SIZE=256
CONFIG_LOG_BACKEND_RTT_BUFFER_SIZE=384
CONFIG_LOG_PROCESS_THREAD_STACK_SIZE=1280
CONFIG_SEGGER_RTT_BUFFER_SIZE_UP=384

# Join handshake (#118 phase 2) pushed this overlay over its flash budget by
# ~900 B. Shell --help text (CONFIG_SHELL_HELP, on via debug.conf) is a sizable
# flash cost across every shell command in the image, none of which this bench
# rig's operator needs interactively (doc/p2p.md §14's commands are already
# scripted/known) -- disabling it is the cheapest lever that doesn't touch any
# code actually under test here.
CONFIG_SHELL_HELP=n

# The single biggest remaining lever (#118 phase 2 flash budget, requested
# ahead of the §6 Ack/retry work): this bench rig only ever exercises P2P
# (radio_mode always p2p), so the LoRaWAN protocol stack itself is dead
# weight here -- ~41 KB flash / ~15 KB RAM per issue #395's measurement on
# the (separate, unmerged) sticker-debug-variants branch. Needed guards in
# app_radio.c (LoRaWAN-fallback calls), main.c (LRW_RESET/LRW_JOIN
# deferred-NFC actions), app_calibration.c (cal-mode uplink handoff), and
# app/CMakeLists.txt (app_report.c moved to unconditional compilation,
# since it owns the sample/history cadence via app_radio, not just the
# LoRaWAN uplink) -- see those commits for #118 phase 2. CONFIG_LORA stays
# on (P2P's own raw-radio driver dependency); only the LoRaWAN protocol
# layer goes.
#
# Turned off via the app-level CONFIG_RADIO_LORAWAN, NOT by assigning
# CONFIG_LORAWAN=n directly (which is what this line used to do, before
# #395 landed on v1.5.0): CONFIG_RADIO_LORAWAN now `select`s LORAWAN, and a
# Kconfig `select` beats an assignment, so the direct form would be silently
# overridden back to y with only a warning.
CONFIG_RADIO_LORAWAN=n

# debug.conf caps compiled-in log severity at 2 (LOG_MAX_LEVEL=2 -> nothing
# below LOG_WRN survives), which drops every LOG_INF line the P2P module
# emits -- and those are exactly the anchors the e2e plan's rows match on
# ("TX type ...", "Ack (counter ...)", "Joined: ..."). Every live row of the
# 2026-09-08 acceptance run needed -DCONFIG_LOG_MAX_LEVEL=3 on the build line
# (+5.3 KB flash, still inside this overlay's budget). Bake it in so a tester
# following doc/p2p-e2e-test-plan.md literally sees the anchors.
CONFIG_LOG_MAX_LEVEL=3

# app_power suspends the node after APP_DEBUG_AUTOSUSPEND_S (default 7200 s)
# without shell activity, and only NRST / a power cycle wakes it. That ended
# three unattended soaks of the 2026-09-08 run at uptime 02:00:2x and looked
# like unexplained reboots. A duty-ledger soak (P2E-16) is >= 70 min by
# design and often left alone longer; 0 disables the timer for this bench
# image only -- production and plain debug.conf keep the default.
CONFIG_APP_DEBUG_AUTOSUSPEND_S=0
```

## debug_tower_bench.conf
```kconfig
# TOWER-over-LoRa P0 bench (throw-away; doc/plan "TOWER protocol as the P2P
# transport" §13.1). Layer on debug.conf + debug_p2p_bench.conf:
#   -DEXTRA_CONF_FILE="debug.conf;debug_p2p_bench.conf;debug_tower_bench.conf"
CONFIG_APP_P2P_TOWER_BENCH=y

# A TWR line is up to ~170 chars; the RTT backend's drop mode cuts each message
# at this size (128 lost the tail fields at SF7 already).
CONFIG_LOG_BACKEND_RTT_MESSAGE_SIZE=192
```

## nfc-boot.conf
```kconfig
# Variant-B NFC firmware update overlay.
#
# Links the application at slot0 (0xC000) behind the NFC bootloader and
# enforces the slot0 size bound, instead of the default flat image from 0x0.
# Use together with the boot/ image:
#   west build -b sticker sticker/app -- -DEXTRA_CONF_FILE=nfc-boot.conf
#
# See doc/nfc-update-protocol.md §7 and boot/README.md.

CONFIG_USE_DT_CODE_PARTITION=y
```

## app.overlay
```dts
#include <zephyr/dt-bindings/gpio/gpio.h>

/ {
	aliases {
		sw0 = &hall_l;
		sw1 = &hall_r;
		sw2 = &gp_a;
		sw3 = &gp_b;
	};

	zephyr,user {
		pir-si-gpios = <&gpioa 11 GPIO_ACTIVE_HIGH>;
		pir-dl-gpios = <&gpiob 4 (GPIO_ACTIVE_HIGH | GPIO_PULL_DOWN)>;
		/* ST25DV GPO interrupt output (U11 pin 11 -> STM32 PB12, EXTI12),
		 * handled in app_nfc.c to wake the NFC handler on RF events. */
		nfc-gpo-gpios = <&gpiob 12 (GPIO_ACTIVE_HIGH | GPIO_PULL_DOWN)>;
	};
};

/* Mark GPIOB (hosts the ST25DV GPO on PB12) as a system wake-up source so the
 * PM subsystem does NOT suspend the port when the CPU enters Stop2. Without this
 * the system-managed PM suspend sweep gates the port and the PB12 EXTI cannot
 * wake the MCU from Stop2 — so a phone tap on a sleeping (release) sticker went
 * unserviced. Paired with pm_device_wakeup_enable(gpiob) in app_nfc_init. */
&gpiob {
	wakeup-source;
};
```

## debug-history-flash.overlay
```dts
/*
 * Copyright (c) 2026 HARDWARIO a.s.
 * SPDX-License-Identifier: Apache-2.0
 *
 * Debug-only test variant: shrink the history_partition to 16 KB (8 x 2 KB
 * erase pages) instead of the release 32 KB, and grow code_partition to
 * absorb the difference, so a debug image (~214 KB) can keep
 * CONFIG_APP_HISTORY_FLASH=y instead of falling back to the RAM ring.
 *
 * storage_partition stays fixed at its release offset/size (0x3C000, 16 KB) —
 * NVS/identity must not move. Pair with debug-history-flash.conf, which sets
 * CONFIG_APP_HISTORY_FLASH=y and CONFIG_FLASH_LOAD_SIZE=0x38000 to match.
 *
 * Purpose: a small ring (8 pages) wraps/evicts in minutes instead of hours,
 * making AT-HIS-03/04/05 (persistence, wrap, torn-tail) and the
 * clock-sync base-time backfill (app_history_on_clock_sync) practical to
 * exercise on a debug build with full RTT shell access, instead of needing
 * a release build (no shell) for anything history-related.
 */

&flash0 {
	partitions {
		/* code_partition keeps its base address (0x0) — just grow it, which
		 * merges into the existing node rather than needing a delete. */
		code_partition: partition@0 {
			reg = <0x00000000 DT_SIZE_K(224)>;
		};

		/* history_partition moves (0x34000 -> 0x38000) and shrinks, so the old
		 * node must be deleted before the new one can reuse the label.
		 * storage_partition (0x3c000, 16 KB) is untouched. */
		/delete-node/ partition@34000;

		history_partition: partition@38000 {
			label = "history";
			reg = <0x00038000 DT_SIZE_K(16)>;
		};
	};
};
```

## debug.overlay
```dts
/*
 * Copyright (c) 2026 HARDWARIO a.s.
 * SPDX-License-Identifier: Apache-2.0
 *
 * Debug-build devicetree overlay, applied automatically whenever debug.conf is
 * in EXTRA_CONF_FILE (see app/CMakeLists.txt).
 *
 * debug.conf sets CONFIG_PM=n, so the kernel tick is the Cortex-M SysTick
 * clocked from the 48 MHz MSI instead of LPTIM1 on the LSE crystal (release).
 * A free-running MSI was measured ~1.22 % slow on the bench, and every kernel
 * timeout (report cadence, LoRaWAN RX windows, retries) drifts with it. MSI PLL
 * mode lets the hardware trim the MSI continuously against the 32.768 kHz LSE,
 * so the debug kernel clock tracks the crystal like the release build.
 *
 * Not applied to release: its tick already runs from the LSE (LPTIM1), and the
 * MSI PLL mode has not been validated there across Stop2 entry/exit.
 */

&clk_msi {
	msi-pll-mode;
};
```

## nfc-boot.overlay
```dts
/*
 * Variant-B flash layout for the application built to run behind the NFC
 * bootloader (doc/nfc-update-protocol.md §7). Same partition table as
 * boot/app.overlay, but here the app links at slot0 (code_partition).
 *
 * Passed explicitly (EXTRA_DTC_OVERLAY_FILE), NOT named app.overlay, so the
 * default flat build (which links from 0x0) is unaffected.
 *
 * Keep the partition table in sync with boot/app.overlay.
 */

#include <zephyr/dt-bindings/dt-util.h>

&flash0 {
	/delete-node/ partitions;

	partitions {
		compatible = "fixed-partitions";
		#address-cells = <1>;
		#size-cells = <1>;

		boot_partition: partition@0 {
			label = "boot";
			reg = <0x00000000 DT_SIZE_K(36)>;
		};

		slot0_partition: code_partition: partition@9000 {
			label = "code";
			reg = <0x00009000 DT_SIZE_K(162)>;
		};

		sfu_meta_partition: partition@31800 {
			label = "sfu_meta";
			reg = <0x00031800 DT_SIZE_K(2)>;
		};

		history_partition: partition@32000 {
			label = "history";
			reg = <0x00032000 DT_SIZE_K(40)>;
		};

		storage_partition: partition@3c000 {
			label = "storage";
			reg = <0x0003c000 DT_SIZE_K(16)>;
		};
	};
};

/ {
	chosen {
		zephyr,code-partition = &code_partition;
	};
};
```

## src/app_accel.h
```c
/*
 * Copyright (c) 2025 HARDWARIO a.s.
 *
 * SPDX-License-Identifier: Apache-2.0
 */

#ifndef APP_ACCEL_H_
#define APP_ACCEL_H_

#include "app_config.h"

#ifdef __cplusplus
extern "C" {
#endif

int app_accel_read(float *accel_x, float *accel_y, float *accel_z, int *orientation);

/* Motion (any-motion) detection via the LIS2DH hardware interrupt. */
typedef void (*app_accel_motion_cb_t)(void *user_data);

/* Register the motion callback and arm the interrupt at the configured
 * sensitivity (g_app_config.accel_motion_sensitivity). Call once at init. */
int app_accel_init_motion(app_accel_motion_cb_t cb, void *user_data);

/* Apply a sensitivity level at runtime. OFF disables the interrupt (power
 * saving); LOW/MEDIUM/HIGH set the slope threshold + duration and (re)arm it. */
int app_accel_set_motion_sensitivity(enum app_config_motion_sensitivity level);

#ifdef __cplusplus
}
#endif

#endif /* APP_ACCEL_H_ */
```

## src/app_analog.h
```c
/*
 * Copyright (c) 2026 HARDWARIO a.s.
 *
 * SPDX-License-Identifier: Apache-2.0
 */

#ifndef APP_ANALOG_H_
#define APP_ANALOG_H_

/* Standard includes */
#include <stdint.h>

#ifdef __cplusplus
extern "C" {
#endif

/* ADC1 access shared by the battery monitor (app_battery.c) and the analog
 * voltage on the external inputs GP_A (PB4, ADC1_IN3) / GP_B (PA11, ADC1_IN7),
 * #396. */

/* One-shot 12-bit read of ADC1 channel `channel_id` in millivolts at the pin.
 * Resumes ADC1, sets the channel up, samples and suspends it again; every
 * caller is serialized on one lock, so concurrent callers never interleave
 * their RESUME/SUSPEND pairs. */
int app_analog_read_mv(uint8_t channel_id, int32_t *mv);

/* Put the GP_A / GP_B pins whose cap_gpio_input_a / _b is analog into analog
 * mode. Call from app_sensor_init() after the pin use is resolved (#498) and
 * after app_input_init(), which configures both pins as digital inputs. */
int app_analog_init(void);

/* Input-referred voltage at the connector (V), divider-corrected (x34, see
 * app_analog.c). *voltage is left untouched on error. */
int app_analog_measure_a(float *voltage);
int app_analog_measure_b(float *voltage);

#ifdef __cplusplus
}
#endif

#endif /* APP_ANALOG_H_ */
```

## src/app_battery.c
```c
/*
 * Copyright (c) 2025 HARDWARIO a.s.
 *
 * SPDX-License-Identifier: Apache-2.0
 */

#include "app_analog.h"
#include "app_led.h"
#include "app_log.h"

/* Zephyr includes */
#include <zephyr/device.h>
#include <zephyr/devicetree.h>
#include <zephyr/kernel.h>
#include <zephyr/logging/log.h>
#include <zephyr/pm/device.h>

/* Standard includes */
#include <errno.h>
#include <math.h>

LOG_MODULE_REGISTER(app_battery, LOG_LEVEL_DBG);

#define ADC_CHANNEL_BATT 2

#define R1_KOHM 560
#define R2_KOHM 100

static const struct device *m_dev = DEVICE_DT_GET(DT_NODELABEL(adc1));

/* Last successfully measured voltage, for callers that must not do a live ADC
 * read from a context where it can hang (#340 M9) - e.g. LoRaWAN DevStatusReq,
 * which runs on the system workqueue and would otherwise race the periodic
 * sensor sampler's own app_battery_measure() call on the same ADC. Own lock so
 * app_battery.c stays self-contained (no dependency on app_sensor.c). */
static float m_last_voltage = NAN;
static K_MUTEX_DEFINE(m_last_voltage_lock);

int app_battery_init(void)
{
	int ret;

	if (!device_is_ready(m_dev)) {
		LOG_ERR("Device not ready");
		return -ENODEV;
	}

	/* The ADC driver boots ADC1 running; park it until the first read
	 * (app_analog_read_mv() resumes and sets the channel up per read). */
#if defined(CONFIG_PM_DEVICE)
	ret = pm_device_action_run(m_dev, PM_DEVICE_ACTION_SUSPEND);
	if (ret && ret != -EALREADY) {
		LOG_ERR_CALL_FAILED_INT("pm_device_action_run", ret);
		return ret;
	}
#endif /* defined(CONFIG_PM_DEVICE) */

	return 0;
}

int app_battery_measure(float *voltage)
{
	int32_t mv;

	int ret = app_analog_read_mv(ADC_CHANNEL_BATT, &mv);
	if (ret) {
		return ret;
	}

	if (voltage) {
		*voltage = mv / 1000.f;
		*voltage = *voltage / R2_KOHM * (R1_KOHM + R2_KOHM);
		LOG_DBG("Battery voltage: %s%d.%02d V", APP_FP2(*voltage));

		k_mutex_lock(&m_last_voltage_lock, K_FOREVER);
		m_last_voltage = *voltage;
		k_mutex_unlock(&m_last_voltage_lock);
	}

	return 0;
}

float app_battery_last_sample(void)
{
	float v;

	k_mutex_lock(&m_last_voltage_lock, K_FOREVER);
	v = m_last_voltage;
	k_mutex_unlock(&m_last_voltage_lock);

	return v;
}
```
